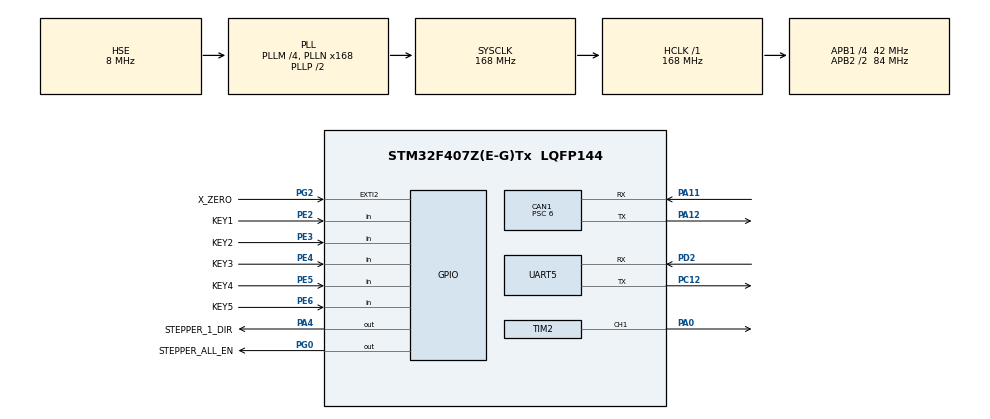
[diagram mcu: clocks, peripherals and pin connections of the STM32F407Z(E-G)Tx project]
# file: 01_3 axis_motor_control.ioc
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CAN1.ABOM=ENABLE
CAN1.AWUM=ENABLE
CAN1.BS1=CAN_BS1_11TQ
CAN1.BS2=CAN_BS2_2TQ
CAN1.CalculateBaudRate=500000
CAN1.CalculateTimeBit=2000
CAN1.CalculateTimeQuantum=142.85714285714286
CAN1.Prescaler=6
Mcu.Family=STM32F4
Mcu.Name=STM32F407Z(E-G)Tx
Mcu.Package=LQFP144
NVIC.EXTI2_IRQn=true\:0\:0\:false\:false\:true\:true\:true\:true
NVIC.PriorityGroup=NVIC_PRIORITYGROUP_4
NVIC.TIM2_IRQn=true\:1\:0\:true\:false\:true\:true\:true\:true
PA0-WKUP.GPIO_Speed=GPIO_SPEED_FREQ_VERY_HIGH
PA0-WKUP.Signal=S_TIM2_CH1_ETR
PA11.Mode=CAN_Activate
PA11.Signal=CAN1_RX
PA12.Mode=CAN_Activate
PA12.Signal=CAN1_TX
PA13.Mode=Serial_Wire
PA13.Signal=SYS_JTMS-SWDIO
PA14.Mode=Serial_Wire
PA14.Signal=SYS_JTCK-SWCLK
PA4.GPIO_Label=STEPPER_1_DIR
PA4.GPIO_Speed=GPIO_SPEED_FREQ_VERY_HIGH
PA4.Signal=GPIO_Output
PC12.Mode=Asynchronous
PC12.Signal=UART5_TX
PC14-OSC32_IN.Mode=LSE-External-Oscillator
PC14-OSC32_IN.Signal=RCC_OSC32_IN
PC15-OSC32_OUT.Mode=LSE-External-Oscillator
PC15-OSC32_OUT.Signal=RCC_OSC32_OUT
PD2.Mode=Asynchronous
PD2.Signal=UART5_RX
PE2.GPIO_Label=KEY1
PE2.GPIO_PuPd=GPIO_PULLUP
PE2.Signal=GPIO_Input
PE3.GPIO_Label=KEY2
PE3.GPIO_PuPd=GPIO_PULLUP
PE3.Signal=GPIO_Input
PE4.GPIO_Label=KEY3
PE4.GPIO_PuPd=GPIO_PULLUP
PE4.Signal=GPIO_Input
PE5.GPIO_Label=KEY4
PE5.GPIO_PuPd=GPIO_PULLUP
PE5.Signal=GPIO_Input
PE6.GPIO_Label=KEY5
PE6.GPIO_PuPd=GPIO_PULLUP
PE6.Signal=GPIO_Input
PG0.GPIO_Label=STEPPER_ALL_EN
PG0.GPIO_Speed=GPIO_SPEED_FREQ_VERY_HIGH
PG0.Signal=GPIO_Output
PG2.GPIO_Label=X_ZERO
PG2.GPIO_ModeDefaultEXTI=GPIO_MODE_IT_FALLING
PG2.GPIO_PuPd=GPIO_PULLUP
PG2.Signal=GPXTI2
PH0-OSC_IN.Mode=HSE-External-Oscillator
PH0-OSC_IN.Signal=RCC_OSC_IN
PH1-OSC_OUT.Mode=HSE-External-Oscillator
PH1-OSC_OUT.Signal=RCC_OSC_OUT
ProjectManager.HeapSize=0x200
ProjectManager.StackSize=0x400
ProjectManager.TargetToolchain=MDK-ARM V5.32
RCC.48MHZClocksFreq_Value=84000000
RCC.AHBFreq_Value=168000000
RCC.APB1CLKDivider=RCC_HCLK_DIV4
RCC.APB1Freq_Value=42000000
RCC.APB1TimFreq_Value=84000000
RCC.APB2CLKDivider=RCC_HCLK_DIV2
RCC.APB2Freq_Value=84000000
RCC.APB2TimFreq_Value=168000000
RCC.CortexFreq_Value=168000000
RCC.HCLKFreq_Value=168000000
RCC.HSE_VALUE=8000000
RCC.HSI_VALUE=16000000
RCC.PLLM=4
RCC.PLLN=168
RCC.PLLSourceVirtual=RCC_PLLSOURCE_HSE
RCC.SYSCLKFreq_VALUE=168000000
RCC.SYSCLKSource=RCC_SYSCLKSOURCE_PLLCLK
RCC.VCOOutputFreq_Value=336000000
SH.S_TIM2_CH1_ETR.0=TIM2_CH1,PWM Generation1 CH1
TIM2.AutoReloadPreload=TIM_AUTORELOAD_PRELOAD_DISABLE
TIM2.Channel-PWM\ Generation1\ CH1=TIM_CHANNEL_1
TIM2.Period=624
TIM2.Prescaler=83
UART5.VirtualMode=Asynchronous
VP_TIM2_VS_ClockSourceINT.Mode=Internal
board=custom

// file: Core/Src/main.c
/* USER CODE BEGIN Header */
/**
  ******************************************************************************
  * @file           : main.c
  * @brief          : Main program body
  ******************************************************************************
  * @attention
  *
  * Copyright (c) 2026 STMicroelectronics.
  * All rights reserved.
  *
  * This software is licensed under terms that can be found in the LICENSE file
  * in the root directory of this software component.
  * If no LICENSE file comes with this software, it is provided AS-IS.
  *
  ******************************************************************************
  */
/* USER CODE END Header */
#include "main.h"
#include "can.h"
#include "tim.h"
#include "usart.h"
#include "gpio.h"

/* USER CODE BEGIN Includes */

#include "App_Main.h"

/* USER CODE END Includes */

void SystemClock_Config(void);

int main(void)
{

  /* MCU Configuration--------------------------------------------------------*/

  /* Reset of all peripherals, Initializes the Flash interface and the Systick. */
  HAL_Init();

  /* Configure the system clock */
  SystemClock_Config();

  /* Initialize all configured peripherals */
  MX_GPIO_Init();
  MX_UART5_Init();
  MX_TIM2_Init();
  MX_CAN1_Init();
  /* USER CODE BEGIN 2 */

  //! @brief 初始化应用主函数
  App_Main();

  /* USER CODE END 2 */

  /* Infinite loop */
  while (1)
  {

  }
}

void SystemClock_Config(void)
{
  RCC_OscInitTypeDef RCC_OscInitStruct = {0};
  RCC_ClkInitTypeDef RCC_ClkInitStruct = {0};

  /** Configure the main internal regulator output voltage
  */
  __HAL_RCC_PWR_CLK_ENABLE();
  __HAL_PWR_VOLTAGESCALING_CONFIG(PWR_REGULATOR_VOLTAGE_SCALE1);

  /** Initializes the RCC Oscillators according to the specified parameters
  * in the RCC_OscInitTypeDef structure.
  */
  RCC_OscInitStruct.OscillatorType = RCC_OSCILLATORTYPE_HSE;
  RCC_OscInitStruct.HSEState = RCC_HSE_ON;
  RCC_OscInitStruct.PLL.PLLState = RCC_PLL_ON;
  RCC_OscInitStruct.PLL.PLLSource = RCC_PLLSOURCE_HSE;
  RCC_OscInitStruct.PLL.PLLM = 4;
  RCC_OscInitStruct.PLL.PLLN = 168;
  RCC_OscInitStruct.PLL.PLLP = RCC_PLLP_DIV2;
  RCC_OscInitStruct.PLL.PLLQ = 4;
  if (HAL_RCC_OscConfig(&RCC_OscInitStruct) != HAL_OK)
  {
    Error_Handler();
  }

  /** Initializes the CPU, AHB and APB buses clocks
  */
  RCC_ClkInitStruct.ClockType = RCC_CLOCKTYPE_HCLK|RCC_CLOCKTYPE_SYSCLK
                              |RCC_CLOCKTYPE_PCLK1|RCC_CLOCKTYPE_PCLK2;
  RCC_ClkInitStruct.SYSCLKSource = RCC_SYSCLKSOURCE_PLLCLK;
  RCC_ClkInitStruct.AHBCLKDivider = RCC_SYSCLK_DIV1;
  RCC_ClkInitStruct.APB1CLKDivider = RCC_HCLK_DIV4;
  RCC_ClkInitStruct.APB2CLKDivider = RCC_HCLK_DIV2;

  if (HAL_RCC_ClockConfig(&RCC_ClkInitStruct, FLASH_LATENCY_5) != HAL_OK)
  {
    Error_Handler();
  }
}

void Error_Handler(void)
{
  __disable_irq();
  while (1)
  {
  }
}
